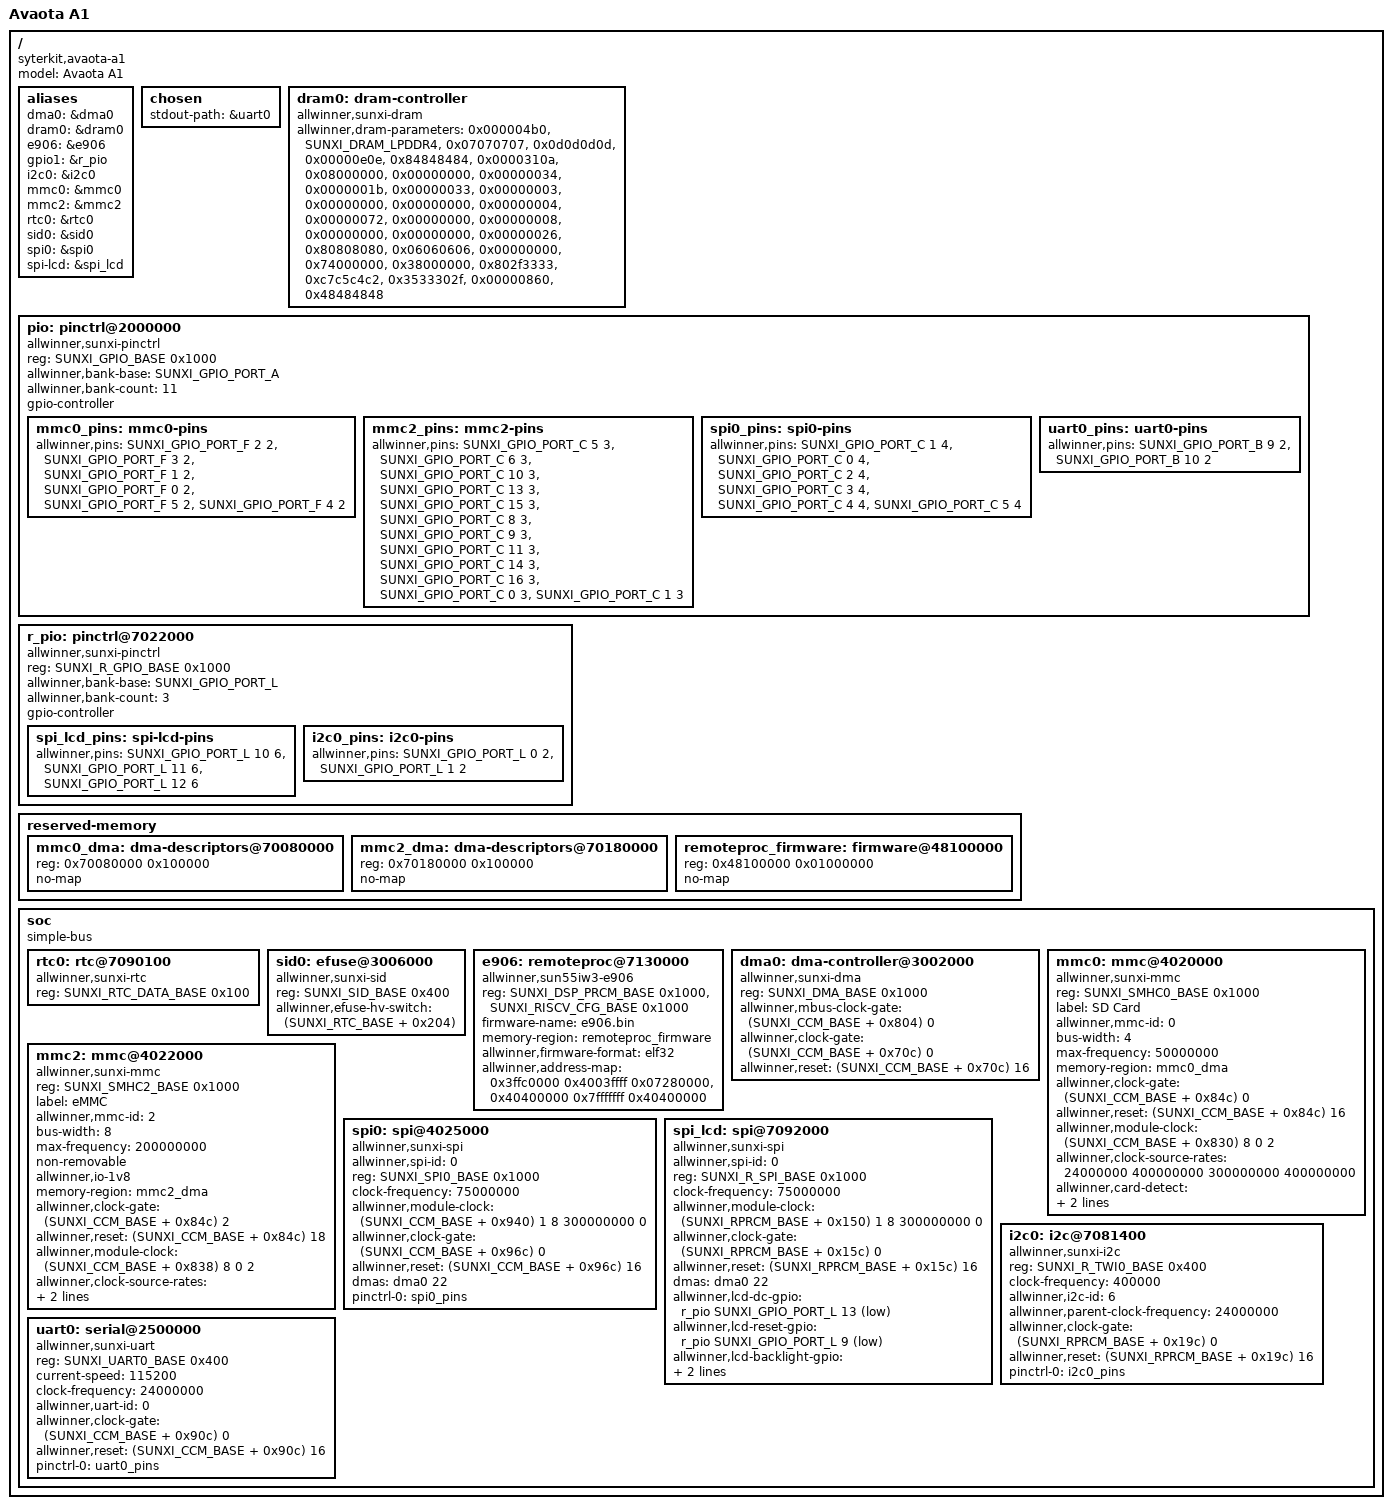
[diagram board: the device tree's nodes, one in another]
// SPDX-License-Identifier: GPL-2.0+
/dts-v1/;

#include <dt-bindings/dram/dram-param.h>

#include <dt-bindings/gpio/sunxi-gpio.h>
#include <dt-bindings/soc/sun55iw3.h>

/ {
	#address-cells = <1>;
	#size-cells = <1>;
	model = "Avaota A1";
	compatible = "syterkit,avaota-a1";

	aliases {
		dma0 = &dma0;
		dram0 = &dram0;
		e906 = &e906;
		gpio1 = &r_pio;
		i2c0 = &i2c0;
		mmc0 = &mmc0;
		mmc2 = &mmc2;
		rtc0 = &rtc0;
		sid0 = &sid0;
		spi0 = &spi0;
		spi-lcd = &spi_lcd;
	};

	chosen {
		stdout-path = &uart0;
	};

	dram0: dram-controller {
		compatible = "allwinner,sunxi-dram";
		allwinner,dram-parameters =
			<0x000004b0>,
			<SUNXI_DRAM_LPDDR4>,
			<0x07070707>,
			<0x0d0d0d0d>,
			<0x00000e0e>,
			<0x84848484>,
			<0x0000310a>,
			<0x08000000>,
			<0x00000000>,
			<0x00000034>,
			<0x0000001b>,
			<0x00000033>,
			<0x00000003>,
			<0x00000000>,
			<0x00000000>,
			<0x00000004>,
			<0x00000072>,
			<0x00000000>,
			<0x00000008>,
			<0x00000000>,
			<0x00000000>,
			<0x00000026>,
			<0x80808080>,
			<0x06060606>,
			<0x00000000>,
			<0x74000000>,
			<0x38000000>,
			<0x802f3333>,
			<0xc7c5c4c2>,
			<0x3533302f>,
			<0x00000860>,
			<0x48484848>;
		status = "okay";
	};

	pio: pinctrl@2000000 {
		compatible = "allwinner,sunxi-pinctrl";
		reg = <SUNXI_GPIO_BASE 0x1000>;
		allwinner,bank-base = <SUNXI_GPIO_PORT_A>;
		allwinner,bank-count = <11>;
		gpio-controller;
		#gpio-cells = <3>;

		mmc0_pins: mmc0-pins {
			allwinner,pins =
				<SUNXI_GPIO_PORT_F 2 2>,
				<SUNXI_GPIO_PORT_F 3 2>,
				<SUNXI_GPIO_PORT_F 1 2>,
				<SUNXI_GPIO_PORT_F 0 2>,
				<SUNXI_GPIO_PORT_F 5 2>,
				<SUNXI_GPIO_PORT_F 4 2>;
		};

		mmc2_pins: mmc2-pins {
			allwinner,pins =
				<SUNXI_GPIO_PORT_C 5 3>,
				<SUNXI_GPIO_PORT_C 6 3>,
				<SUNXI_GPIO_PORT_C 10 3>,
				<SUNXI_GPIO_PORT_C 13 3>,
				<SUNXI_GPIO_PORT_C 15 3>,
				<SUNXI_GPIO_PORT_C 8 3>,
				<SUNXI_GPIO_PORT_C 9 3>,
				<SUNXI_GPIO_PORT_C 11 3>,
				<SUNXI_GPIO_PORT_C 14 3>,
				<SUNXI_GPIO_PORT_C 16 3>,
				<SUNXI_GPIO_PORT_C 0 3>,
				<SUNXI_GPIO_PORT_C 1 3>;
		};

		spi0_pins: spi0-pins {
			allwinner,pins =
				<SUNXI_GPIO_PORT_C 1 4>,
				<SUNXI_GPIO_PORT_C 0 4>,
				<SUNXI_GPIO_PORT_C 2 4>,
				<SUNXI_GPIO_PORT_C 3 4>,
				<SUNXI_GPIO_PORT_C 4 4>,
				<SUNXI_GPIO_PORT_C 5 4>;
		};

		uart0_pins: uart0-pins {
			allwinner,pins =
				<SUNXI_GPIO_PORT_B 9 2>,
				<SUNXI_GPIO_PORT_B 10 2>;
		};
	};

	r_pio: pinctrl@7022000 {
		compatible = "allwinner,sunxi-pinctrl";
		reg = <SUNXI_R_GPIO_BASE 0x1000>;
		allwinner,bank-base = <SUNXI_GPIO_PORT_L>;
		allwinner,bank-count = <3>;
		gpio-controller;
		#gpio-cells = <3>;

		spi_lcd_pins: spi-lcd-pins {
			allwinner,pins =
				<SUNXI_GPIO_PORT_L 10 6>,
				<SUNXI_GPIO_PORT_L 11 6>,
				<SUNXI_GPIO_PORT_L 12 6>;
		};

		i2c0_pins: i2c0-pins {
			allwinner,pins =
				<SUNXI_GPIO_PORT_L 0 2>,
				<SUNXI_GPIO_PORT_L 1 2>;
		};
	};

	reserved-memory {
		#address-cells = <1>;
		#size-cells = <1>;
		ranges;

		mmc0_dma: dma-descriptors@70080000 {
			reg = <0x70080000 0x100000>;
			no-map;
		};

		mmc2_dma: dma-descriptors@70180000 {
			reg = <0x70180000 0x100000>;
			no-map;
		};

		remoteproc_firmware: firmware@48100000 {
			reg = <0x48100000 0x01000000>;
			no-map;
		};
	};

	soc {
		compatible = "simple-bus";
		#address-cells = <1>;
		#size-cells = <1>;
		ranges;

		rtc0: rtc@7090100 {
			compatible = "allwinner,sunxi-rtc";
			reg = <SUNXI_RTC_DATA_BASE 0x100>;
			status = "okay";
		};

		sid0: efuse@3006000 {
			compatible = "allwinner,sunxi-sid";
			reg = <SUNXI_SID_BASE 0x400>;
			allwinner,efuse-hv-switch = <(SUNXI_RTC_BASE + 0x204)>;
			status = "okay";
		};

		e906: remoteproc@7130000 {
			compatible = "allwinner,sun55iw3-e906";
			reg = <SUNXI_DSP_PRCM_BASE 0x1000>,
			      <SUNXI_RISCV_CFG_BASE 0x1000>;
			firmware-name = "e906.bin";
			memory-region = <&remoteproc_firmware>;
			allwinner,firmware-format = "elf32";
			allwinner,address-map =
				<0x3ffc0000 0x4003ffff 0x07280000>,
				<0x40400000 0x7fffffff 0x40400000>;
			status = "okay";
		};

		dma0: dma-controller@3002000 {
			compatible = "allwinner,sunxi-dma";
			reg = <SUNXI_DMA_BASE 0x1000>;
			#dma-cells = <1>;
			allwinner,mbus-clock-gate = <(SUNXI_CCM_BASE + 0x804) 0>;
			allwinner,clock-gate = <(SUNXI_CCM_BASE + 0x70c) 0>;
			allwinner,reset = <(SUNXI_CCM_BASE + 0x70c) 16>;
			status = "okay";
		};

		mmc0: mmc@4020000 {
			compatible = "allwinner,sunxi-mmc";
			reg = <SUNXI_SMHC0_BASE 0x1000>;
			label = "SD Card";
			allwinner,mmc-id = <0>;
			bus-width = <4>;
			max-frequency = <50000000>;
			memory-region = <&mmc0_dma>;
			allwinner,clock-gate = <(SUNXI_CCM_BASE + 0x84c) 0>;
			allwinner,reset = <(SUNXI_CCM_BASE + 0x84c) 16>;
			allwinner,module-clock =
				<(SUNXI_CCM_BASE + 0x830) 8 0 2>;
			allwinner,clock-source-rates =
				<24000000 400000000 300000000 400000000>;
			allwinner,card-detect =
				<&pio SUNXI_GPIO_PORT_F 6 0 0>;
			pinctrl-names = "default";
			pinctrl-0 = <&mmc0_pins>;
			status = "okay";
		};

		mmc2: mmc@4022000 {
			compatible = "allwinner,sunxi-mmc";
			reg = <SUNXI_SMHC2_BASE 0x1000>;
			label = "eMMC";
			allwinner,mmc-id = <2>;
			bus-width = <8>;
			max-frequency = <200000000>;
			non-removable;
			allwinner,io-1v8;
			memory-region = <&mmc2_dma>;
			allwinner,clock-gate = <(SUNXI_CCM_BASE + 0x84c) 2>;
			allwinner,reset = <(SUNXI_CCM_BASE + 0x84c) 18>;
			allwinner,module-clock =
				<(SUNXI_CCM_BASE + 0x838) 8 0 2>;
			allwinner,clock-source-rates =
				<24000000 800000000 600000000 800000000>;
			pinctrl-names = "default";
			pinctrl-0 = <&mmc2_pins>;
			status = "okay";
		};

		spi0: spi@4025000 {
			compatible = "allwinner,sunxi-spi";
			allwinner,spi-id = <0>;
			reg = <SUNXI_SPI0_BASE 0x1000>;
			clock-frequency = <75000000>;
			allwinner,module-clock = <(SUNXI_CCM_BASE + 0x940) 1 8 300000000 0>;
			allwinner,clock-gate = <(SUNXI_CCM_BASE + 0x96c) 0>;
			allwinner,reset = <(SUNXI_CCM_BASE + 0x96c) 16>;
			dmas = <&dma0 22>;
			dma-names = "rx";
			pinctrl-names = "default";
			pinctrl-0 = <&spi0_pins>;
			status = "okay";
		};

		spi_lcd: spi@7092000 {
			compatible = "allwinner,sunxi-spi";
			allwinner,spi-id = <0>;
			reg = <SUNXI_R_SPI_BASE 0x1000>;
			clock-frequency = <75000000>;
			allwinner,module-clock =
				<(SUNXI_RPRCM_BASE + 0x150) 1 8 300000000 0>;
			allwinner,clock-gate = <(SUNXI_RPRCM_BASE + 0x15c) 0>;
			allwinner,reset = <(SUNXI_RPRCM_BASE + 0x15c) 16>;
			dmas = <&dma0 22>;
			dma-names = "rx";
			allwinner,lcd-dc-gpio =
				<&r_pio SUNXI_GPIO_PORT_L 13 1>;
			allwinner,lcd-reset-gpio =
				<&r_pio SUNXI_GPIO_PORT_L 9 1>;
			allwinner,lcd-backlight-gpio =
				<&r_pio SUNXI_GPIO_PORT_L 8 1>;
			pinctrl-names = "default";
			pinctrl-0 = <&spi_lcd_pins>;
			status = "okay";
		};

		i2c0: i2c@7081400 {
			compatible = "allwinner,sunxi-i2c";
			#address-cells = <1>;
			#size-cells = <0>;
			reg = <SUNXI_R_TWI0_BASE 0x400>;
			clock-frequency = <400000>;
			allwinner,i2c-id = <6>;
			allwinner,parent-clock-frequency = <24000000>;
			allwinner,clock-gate = <(SUNXI_RPRCM_BASE + 0x19c) 0>;
			allwinner,reset = <(SUNXI_RPRCM_BASE + 0x19c) 16>;
			pinctrl-names = "default";
			pinctrl-0 = <&i2c0_pins>;
			status = "okay";

		};

		uart0: serial@2500000 {
			compatible = "allwinner,sunxi-uart";
			reg = <SUNXI_UART0_BASE 0x400>;
			current-speed = <115200>;
			clock-frequency = <24000000>;
			allwinner,uart-id = <0>;
			allwinner,clock-gate = <(SUNXI_CCM_BASE + 0x90c) 0>;
			allwinner,reset = <(SUNXI_CCM_BASE + 0x90c) 16>;
			pinctrl-names = "default";
			pinctrl-0 = <&uart0_pins>;
			status = "okay";
		};
	};
};
